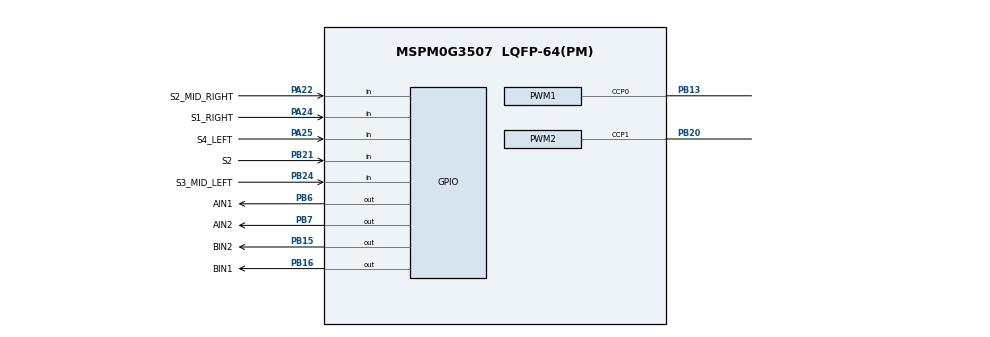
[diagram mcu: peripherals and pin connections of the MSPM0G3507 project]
/**
 * AI AGENTS: Do not edit this file directly. There is no validation or error feedback when
 * editing manually — mistakes will be silent until the file is loaded in SysConfig.
 * Use the SysConfig MCP server instead to make changes with immediate error reporting.
 *
 * These arguments were used when this file was generated. They will be automatically applied on subsequent loads
 * via the GUI or CLI. Run CLI with '--help' for additional information on how to override these arguments.
 * @cliArgs --device "MSPM0G350X" --part "Default" --package "LQFP-64(PM)" --product "mspm0_sdk@2.10.00.04"
 * @v2CliArgs --device "MSPM0G3507" --package "LQFP-64(PM)" --product "mspm0_sdk@2.10.00.04"
 * @versions {"tool":"1.28.0+4696"}
 */

/**
 * Import the modules used in this configuration.
 */
const GPIO   = scripting.addModule("/ti/driverlib/GPIO", {}, false);
const GPIO1  = GPIO.addInstance();
const GPIO2  = GPIO.addInstance();
const GPIO3  = GPIO.addInstance();
const PWM    = scripting.addModule("/ti/driverlib/PWM", {}, false);
const PWM1   = PWM.addInstance();
const PWM2   = PWM.addInstance();
const SYSCTL = scripting.addModule("/ti/driverlib/SYSCTL");

/**
 * Write custom configuration values to the imported modules.
 */
GPIO1.$name                         = "GPIO_MOTOR_DIR";
GPIO1.associatedPins.create(4);
GPIO1.associatedPins[0].$name       = "AIN1";
GPIO1.associatedPins[0].ioStructure = "SD";
GPIO1.associatedPins[0].pin.$assign = "PB6";
GPIO1.associatedPins[1].$name       = "AIN2";
GPIO1.associatedPins[1].ioStructure = "SD";
GPIO1.associatedPins[1].pin.$assign = "PB7";
GPIO1.associatedPins[2].$name       = "BIN1";
GPIO1.associatedPins[2].ioStructure = "SD";
GPIO1.associatedPins[2].pin.$assign = "PB16";
GPIO1.associatedPins[3].$name       = "BIN2";
GPIO1.associatedPins[3].ioStructure = "SD";
GPIO1.associatedPins[3].pin.$assign = "PB15";

const Board = scripting.addModule("/ti/driverlib/Board", {}, false);

GPIO2.$name                              = "GPIO_START_BUTTON";
GPIO2.associatedPins[0].$name            = "S2";
GPIO2.associatedPins[0].direction        = "INPUT";
GPIO2.associatedPins[0].ioStructure      = "SD";
GPIO2.associatedPins[0].internalResistor = "PULL_UP";
GPIO2.associatedPins[0].pin.$assign      = "PB21";

GPIO3.$name                         = "GPIO_LINE_SENSOR";
GPIO3.associatedPins.create(4);
GPIO3.associatedPins[0].$name       = "S1_RIGHT";
GPIO3.associatedPins[0].direction   = "INPUT";
GPIO3.associatedPins[0].ioStructure = "SD";
GPIO3.associatedPins[0].pin.$assign = "PA24";
GPIO3.associatedPins[1].$name       = "S2_MID_RIGHT";
GPIO3.associatedPins[1].direction   = "INPUT";
GPIO3.associatedPins[1].ioStructure = "SD";
GPIO3.associatedPins[1].pin.$assign = "PA22";
GPIO3.associatedPins[2].$name       = "S3_MID_LEFT";
GPIO3.associatedPins[2].direction   = "INPUT";
GPIO3.associatedPins[2].ioStructure = "SD";
GPIO3.associatedPins[2].pin.$assign = "PB24";
GPIO3.associatedPins[3].$name       = "S4_LEFT";
GPIO3.associatedPins[3].direction   = "INPUT";
GPIO3.associatedPins[3].ioStructure = "SD";
GPIO3.associatedPins[3].pin.$assign = "PA25";

PWM1.$name                              = "PWM_MOTOR_B";
PWM1.ccIndex                            = [0];
PWM1.PWM_CHANNEL_0.$name                = "ti_driverlib_pwm_PWMTimerCC0";
PWM1.ccp0PinConfig.$name                = "ti_driverlib_gpio_GPIOPinGeneric0";
PWM1.ccp0PinConfig.direction            = scripting.forceWrite("OUTPUT");
PWM1.ccp0PinConfig.hideOutputInversion  = scripting.forceWrite(false);
PWM1.ccp0PinConfig.onlyInternalResistor = scripting.forceWrite(false);
PWM1.ccp0PinConfig.passedPeripheralType = scripting.forceWrite("Digital");
PWM1.peripheral.ccp0Pin.$assign         = "PB13";

PWM2.$name                              = "PWM_MOTOR_A";
PWM2.ccIndex                            = [1];
PWM2.ccp1PinConfig.$name                = "ti_driverlib_gpio_GPIOPinGeneric2";
PWM2.ccp1PinConfig.direction            = scripting.forceWrite("OUTPUT");
PWM2.ccp1PinConfig.hideOutputInversion  = scripting.forceWrite(false);
PWM2.ccp1PinConfig.onlyInternalResistor = scripting.forceWrite(false);
PWM2.ccp1PinConfig.passedPeripheralType = scripting.forceWrite("Digital");
PWM2.peripheral.ccp1Pin.$assign         = "PB20";
PWM2.PWM_CHANNEL_1.$name                = "ti_driverlib_pwm_PWMTimerCC1";

SYSCTL.forceDefaultClkConfig = true;

/**
 * Pinmux solution for unlocked pins/peripherals. This ensures that minor changes to the automatic solver in a future
 * version of the tool will not impact the pinmux you originally saw.  These lines can be completely deleted in order to
 * re-solve from scratch.
 */
Board.peripheral.$suggestSolution          = "DEBUGSS";
Board.peripheral.swclkPin.$suggestSolution = "PA20";
Board.peripheral.swdioPin.$suggestSolution = "PA19";
PWM1.peripheral.$suggestSolution           = "TIMG12";
PWM2.peripheral.$suggestSolution           = "TIMA0";
SYSCTL.peripheral.$suggestSolution         = "SYSCTL";
